# EG32M0x register map
Vendor: EGmicro Ltd.; Series: EG32M0x; File version: 1.0
CPU: CM0 r0p0, little endian, no MPU, no FPU, 3 interrupt priority bits
Registers are 32-bit, read-write, reset 0x0 unless marked. A register's access mark holds for its fields unless they carry their own. Offsets are from the block's base; [hi:lo] are bit positions; {n}, {i} and the like mark numbered series.

## COMP0 — COMP0 unit
Base 0x40020370
Same registers: COMP1 0x40020380
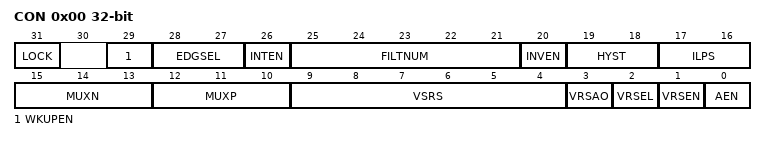
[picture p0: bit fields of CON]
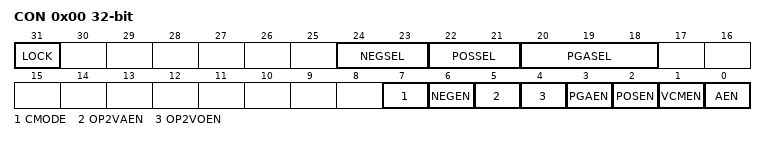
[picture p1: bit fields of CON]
0x00 CON
  [31] LOCK
  [29] WKUPEN — Comparator wake up
  [28:27] EDGSEL — Edge detection selection
  [26] INTEN — Interrupt switch
  [25:21] FILTNUM — Filter coefficient
  [20] INVEN — The output of the comparator is inverted
  [19:18] HYST — Hysteresis voltage selection
  [17:16] ILPS — Low power control
  [15:13] MUXN — Negative input
  [12:10] MUXP — Positive input
  [9:4] VSRS — Internal 6bit DAC voltage gear
  [3] VRSAO — Internal 6bit DAC output via VRSAOUT
  [2] VRSEL — Internal 6bit DAC reference source
  [1] VRSEN — Internal 6bit DAC switch
  [0] AEN — Comparator module switch
0x04 STA
  [0] PEND — Comparator PEND bit

## OPAM0 — OPAM0 unit
Base 0x40020390
Same registers: OPAM1 0x40020398
0x00 CON
  [31] LOCK
  [24:23] NEGSEL — Negative input selection
  [22:21] POSSEL — Positive input selection
  [20:18] PGASEL — Unipolar/differential internal gain selection
  [7] CMODE — Working mode
  [6] NEGEN — Negative input switch
  [5] OP2VAEN — The op amp outputs to the ADC switch
  [4] OP2VOEN — The op amp outputs to the IO switch
  [3] PGAEN — Internal gain switch
  [2] POSEN — Positive input switch
  [1] VCMEN — VCM voltage mode
  [0] AEN — OPAM module switch

## WDT — WDT unit
Base 0x40020190
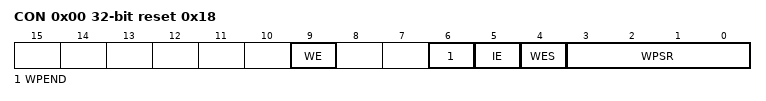
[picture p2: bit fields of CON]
0x00 CON reset 0x18
  [9] WE — Wake up enable
  [6] WPEND — The guard dog counts up the signs
  [5] IE — Interrupt enablement
  [4] WES — Watchdog enabled status
  [3:0] WPSR — Frequency division coefficient
0x04 KEY
  [15:0] KEY — WDT key

## WWDG — WWDG unit
Base 0x400201A0
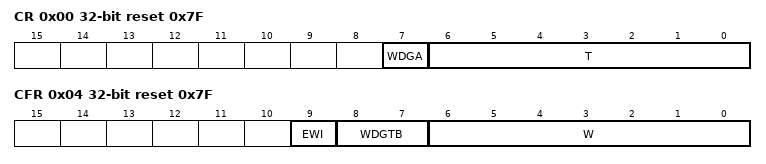
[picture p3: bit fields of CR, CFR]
0x00 CR reset 0x7F
  [7] WDGA — Activation bit
  [6:0] T — 7-bit counter
0x04 CFR reset 0x7F
  [9] EWI — Wake up early interrupt
  [8:7] WDGTB — Time base
  [6:0] W — 7 bit window value
0x08 SR reset 0x7F
  [0] EWIF — Wake up early interrupt flag

## DMA — DMA unit
Base 0x40030000
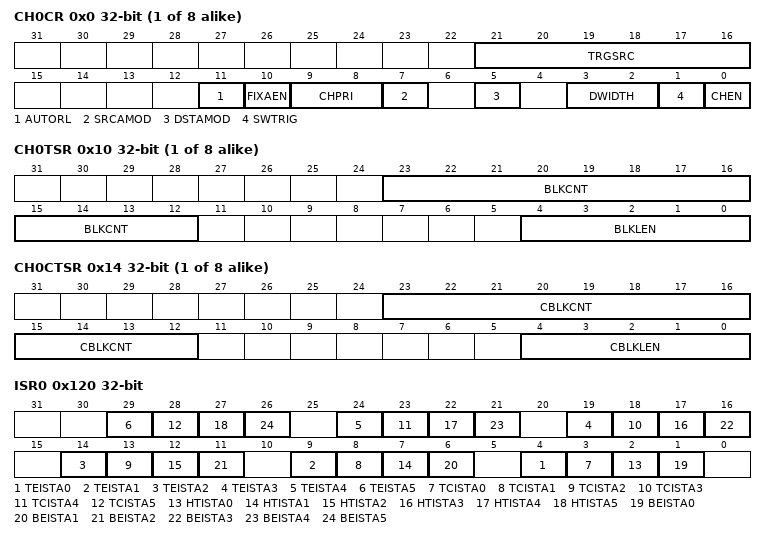
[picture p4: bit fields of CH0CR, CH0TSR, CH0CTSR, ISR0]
{0x0+0x18*i} CH{i}CR (i=0..7)
  [21:16] TRGSRC — Hardware is sent from peripherals
  [11] AUTORL — Channel {i} Automatic overload enable control bit
  [10] FIXAEN — Channel {i} Fixed address enable control bit
  [9:8] CHPRI — Priority of channel {i}
  [7] SRCAMOD — Channel {i} Source address mode selection bit
  [5] DSTAMOD — Channel {i} Destination address mode selection bit
  [3:2] DWIDTH — Data bit width select bit
  [1] SWTRIG — Software trigger control bit
  [0] CHEN — Channel {i} Enable control bit
{0x4+0x18*i} CH{i}SADR (i=0..7)
  [31:0] SADR — Channel {i} Source address
{0x8+0x18*i} CH{i}DADR (i=0..7)
  [31:0] DADR — Channel {i} Destination address
{0x10+0x18*i} CH{i}TSR (i=0..7)
  [23:12] BLKCNT — Number of channel {i} blocks processed
  [4:0] BLKLEN — Length of the channel {i} block
{0x14+0x18*i} CH{i}CTSR (i=0..7)
  [23:12] CBLKCNT — Channel {i} Indicates the number of blocks
  [4:0] CBLKLEN — Channel {i} Indicates the current block length
0x120 ISR0
  [5n+4] TEISTA{n} (n=0..5) — Channel {n} Transmission error interrupt status bit
  [5n+3] TCISTA{n} (n=0..5) — Channel {n} Transmission completion interrupt status bit
  [5n+2] HTISTA{n} (n=0..5) — Channel {n} half transmission interrupt status bit
  [5n+1] BEISTA{n} (n=0..5) — Channel {n} block processing end interrupt status bit
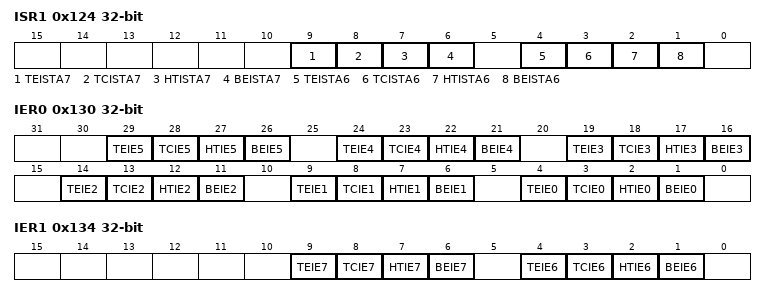
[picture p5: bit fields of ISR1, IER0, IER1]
0x124 ISR1
  [9] TEISTA7 — Channel 7 Transmission error interrupt status bit
  [8] TCISTA7 — Channel 7 Transmission completion interrupt status bit
  [7] HTISTA7 — Channel 7 half transmission interrupt status bit
  [6] BEISTA7 — Channel 7 block processing end interrupt status bit
  [4] TEISTA6 — Channel 6 Transmission error interrupt status bit
  [3] TCISTA6 — Channel 6 Transmission completion interrupt status bit
  [2] HTISTA6 — Channel 6 half transmission interrupt status bit
  [1] BEISTA6 — Channel 6 block processing end interrupt status bit
0x130 IER0
  [5n+4] TEIE{n} (n=0..5) — Channel {n} Transmission error interrupt enable control bit
  [5n+3] TCIE{n} (n=0..5) — Channel {n} Transmission complete interrupt enable control bit
  [5n+2] HTIE{n} (n=0..5) — Channel {n} half transmission interrupt enable control bit
  [5n+1] BEIE{n} (n=0..5) — Channel {n} block processing end interrupt enable control bit
0x134 IER1
  [9] TEIE7 — Channel 7 Transmission error interrupt enable control bit
  [8] TCIE7 — Channel 7 Transmission complete interrupt enable control bit
  [7] HTIE7 — Channel 7 half transmission interrupt enable control bit
  [6] BEIE7 — Channel 7 block processing end interrupt enable control bit
  [4] TEIE6 — Channel 6 Transmission error interrupt enable control bit
  [3] TCIE6 — Channel 6 Transmission complete interrupt enable control bit
  [2] HTIE6 — Channel 6 half transmission interrupt enable control bit
  [1] BEIE6 — Channel 6 block processing end interrupt enable control bit
